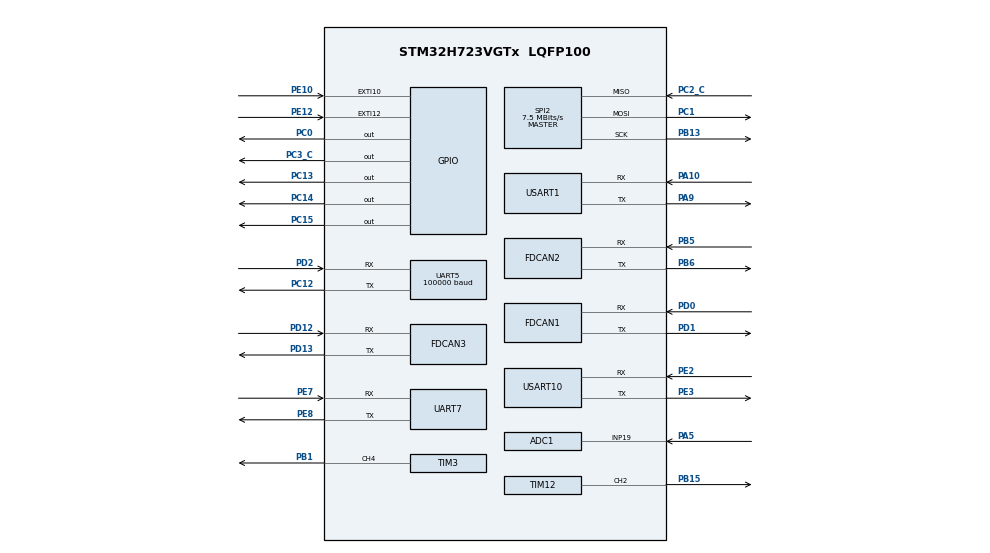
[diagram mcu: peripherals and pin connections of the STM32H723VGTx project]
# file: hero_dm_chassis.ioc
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ADC1.Channel-3\#ChannelRegularConversion=ADC_CHANNEL_19
ADC1.ClockPrescaler=ADC_CLOCK_ASYNC_DIV4
ADC1.ContinuousConvMode=ENABLE
ADC1.ConversionDataManagement=ADC_CONVERSIONDATA_DMA_CIRCULAR
ADC1.EnableInjectedConversion=DISABLE
ADC1.NbrOfConversionFlag=1
ADC1.OffsetNumber-3\#ChannelRegularConversion=ADC_OFFSET_NONE
ADC1.OffsetSignedSaturation-3\#ChannelRegularConversion=DISABLE
ADC1.Rank-3\#ChannelRegularConversion=1
ADC1.Ratio=1
ADC1.SamplingTime-3\#ChannelRegularConversion=ADC_SAMPLETIME_64CYCLES_5
ADC1.master=1
CORTEX_M7.default_mode_Activation=1
Dma.ADC1.5.Direction=DMA_PERIPH_TO_MEMORY
Dma.ADC1.5.EventEnable=DISABLE
Dma.ADC1.5.FIFOMode=DMA_FIFOMODE_DISABLE
Dma.ADC1.5.Instance=DMA1_Stream5
Dma.ADC1.5.MemDataAlignment=DMA_MDATAALIGN_HALFWORD
Dma.ADC1.5.MemInc=DMA_MINC_ENABLE
Dma.ADC1.5.Mode=DMA_CIRCULAR
Dma.ADC1.5.PeriphDataAlignment=DMA_PDATAALIGN_HALFWORD
Dma.ADC1.5.PeriphInc=DMA_PINC_DISABLE
Dma.ADC1.5.Polarity=HAL_DMAMUX_REQ_GEN_RISING
Dma.ADC1.5.Priority=DMA_PRIORITY_LOW
Dma.ADC1.5.RequestNumber=1
Dma.ADC1.5.SignalID=NONE
Dma.ADC1.5.SyncEnable=DISABLE
Dma.ADC1.5.SyncPolarity=HAL_DMAMUX_SYNC_NO_EVENT
Dma.ADC1.5.SyncRequestNumber=1
Dma.ADC1.5.SyncSignalID=NONE
Dma.Request0=UART7_RX
Dma.Request1=SPI2_RX
Dma.Request2=SPI2_TX
Dma.Request3=USART10_RX
Dma.Request4=UART5_RX
Dma.Request5=ADC1
Dma.Request6=USART10_TX
Dma.Request7=USART1_RX
Dma.SPI2_RX.1.Direction=DMA_PERIPH_TO_MEMORY
Dma.SPI2_RX.1.EventEnable=DISABLE
Dma.SPI2_RX.1.FIFOMode=DMA_FIFOMODE_DISABLE
Dma.SPI2_RX.1.Instance=DMA1_Stream0
Dma.SPI2_RX.1.MemDataAlignment=DMA_MDATAALIGN_BYTE
Dma.SPI2_RX.1.MemInc=DMA_MINC_ENABLE
Dma.SPI2_RX.1.Mode=DMA_NORMAL
Dma.SPI2_RX.1.PeriphDataAlignment=DMA_PDATAALIGN_BYTE
Dma.SPI2_RX.1.PeriphInc=DMA_PINC_DISABLE
Dma.SPI2_RX.1.Polarity=HAL_DMAMUX_REQ_GEN_RISING
Dma.SPI2_RX.1.Priority=DMA_PRIORITY_HIGH
Dma.SPI2_RX.1.RequestNumber=1
Dma.SPI2_RX.1.SignalID=NONE
Dma.SPI2_RX.1.SyncEnable=DISABLE
Dma.SPI2_RX.1.SyncPolarity=HAL_DMAMUX_SYNC_NO_EVENT
Dma.SPI2_RX.1.SyncRequestNumber=1
Dma.SPI2_RX.1.SyncSignalID=NONE
Dma.SPI2_TX.2.Direction=DMA_MEMORY_TO_PERIPH
Dma.SPI2_TX.2.EventEnable=DISABLE
Dma.SPI2_TX.2.FIFOMode=DMA_FIFOMODE_DISABLE
Dma.SPI2_TX.2.Instance=DMA1_Stream1
Dma.SPI2_TX.2.MemDataAlignment=DMA_MDATAALIGN_BYTE
Dma.SPI2_TX.2.MemInc=DMA_MINC_ENABLE
Dma.SPI2_TX.2.Mode=DMA_NORMAL
Dma.SPI2_TX.2.PeriphDataAlignment=DMA_PDATAALIGN_BYTE
Dma.SPI2_TX.2.PeriphInc=DMA_PINC_DISABLE
Dma.SPI2_TX.2.Polarity=HAL_DMAMUX_REQ_GEN_RISING
Dma.SPI2_TX.2.Priority=DMA_PRIORITY_HIGH
Dma.SPI2_TX.2.RequestNumber=1
Dma.SPI2_TX.2.SignalID=NONE
Dma.SPI2_TX.2.SyncEnable=DISABLE
Dma.SPI2_TX.2.SyncPolarity=HAL_DMAMUX_SYNC_NO_EVENT
Dma.SPI2_TX.2.SyncRequestNumber=1
Dma.SPI2_TX.2.SyncSignalID=NONE
Dma.UART5_RX.4.Direction=DMA_PERIPH_TO_MEMORY
Dma.UART5_RX.4.EventEnable=DISABLE
Dma.UART5_RX.4.FIFOMode=DMA_FIFOMODE_DISABLE
Dma.UART5_RX.4.Instance=DMA1_Stream4
Dma.UART5_RX.4.MemDataAlignment=DMA_MDATAALIGN_BYTE
Dma.UART5_RX.4.MemInc=DMA_MINC_ENABLE
Dma.UART5_RX.4.Mode=DMA_CIRCULAR
Dma.UART5_RX.4.PeriphDataAlignment=DMA_PDATAALIGN_BYTE
Dma.UART5_RX.4.PeriphInc=DMA_PINC_DISABLE
Dma.UART5_RX.4.Polarity=HAL_DMAMUX_REQ_GEN_RISING
Dma.UART5_RX.4.Priority=DMA_PRIORITY_LOW
Dma.UART5_RX.4.RequestNumber=1
Dma.UART5_RX.4.SignalID=NONE
Dma.UART5_RX.4.SyncEnable=DISABLE
Dma.UART5_RX.4.SyncPolarity=HAL_DMAMUX_SYNC_NO_EVENT
Dma.UART5_RX.4.SyncRequestNumber=1
Dma.UART5_RX.4.SyncSignalID=NONE
Dma.UART7_RX.0.Direction=DMA_PERIPH_TO_MEMORY
Dma.UART7_RX.0.EventEnable=DISABLE
Dma.UART7_RX.0.FIFOMode=DMA_FIFOMODE_DISABLE
Dma.UART7_RX.0.Instance=DMA1_Stream2
Dma.UART7_RX.0.MemDataAlignment=DMA_MDATAALIGN_BYTE
Dma.UART7_RX.0.MemInc=DMA_MINC_ENABLE
Dma.UART7_RX.0.Mode=DMA_NORMAL
Dma.UART7_RX.0.PeriphDataAlignment=DMA_PDATAALIGN_BYTE
Dma.UART7_RX.0.PeriphInc=DMA_PINC_DISABLE
Dma.UART7_RX.0.Polarity=HAL_DMAMUX_REQ_GEN_RISING
Dma.UART7_RX.0.Priority=DMA_PRIORITY_LOW
Dma.UART7_RX.0.RequestNumber=1
Dma.UART7_RX.0.SignalID=NONE
Dma.UART7_RX.0.SyncEnable=DISABLE
Dma.UART7_RX.0.SyncPolarity=HAL_DMAMUX_SYNC_NO_EVENT
Dma.UART7_RX.0.SyncRequestNumber=1
Dma.UART7_RX.0.SyncSignalID=NONE
Dma.USART10_RX.3.Direction=DMA_PERIPH_TO_MEMORY
Dma.USART10_RX.3.EventEnable=DISABLE
Dma.USART10_RX.3.FIFOMode=DMA_FIFOMODE_DISABLE
Dma.USART10_RX.3.Instance=DMA1_Stream3
Dma.USART10_RX.3.MemDataAlignment=DMA_MDATAALIGN_BYTE
Dma.USART10_RX.3.MemInc=DMA_MINC_ENABLE
Dma.USART10_RX.3.Mode=DMA_NORMAL
Dma.USART10_RX.3.PeriphDataAlignment=DMA_PDATAALIGN_BYTE
Dma.USART10_RX.3.PeriphInc=DMA_PINC_DISABLE
Dma.USART10_RX.3.Polarity=HAL_DMAMUX_REQ_GEN_RISING
Dma.USART10_RX.3.Priority=DMA_PRIORITY_LOW
Dma.USART10_RX.3.RequestNumber=1
Dma.USART10_RX.3.SignalID=NONE
Dma.USART10_RX.3.SyncEnable=DISABLE
Dma.USART10_RX.3.SyncPolarity=HAL_DMAMUX_SYNC_NO_EVENT
Dma.USART10_RX.3.SyncRequestNumber=1
Dma.USART10_RX.3.SyncSignalID=NONE
Dma.USART10_TX.6.Direction=DMA_MEMORY_TO_PERIPH
Dma.USART10_TX.6.EventEnable=DISABLE
Dma.USART10_TX.6.FIFOMode=DMA_FIFOMODE_DISABLE
Dma.USART10_TX.6.Instance=DMA1_Stream6
Dma.USART10_TX.6.MemDataAlignment=DMA_MDATAALIGN_BYTE
Dma.USART10_TX.6.MemInc=DMA_MINC_ENABLE
Dma.USART10_TX.6.Mode=DMA_NORMAL
Dma.USART10_TX.6.PeriphDataAlignment=DMA_PDATAALIGN_BYTE
Dma.USART10_TX.6.PeriphInc=DMA_PINC_DISABLE
Dma.USART10_TX.6.Polarity=HAL_DMAMUX_REQ_GEN_RISING
Dma.USART10_TX.6.Priority=DMA_PRIORITY_LOW
Dma.USART10_TX.6.RequestNumber=1
Dma.USART10_TX.6.SignalID=NONE
Dma.USART10_TX.6.SyncEnable=DISABLE
Dma.USART10_TX.6.SyncPolarity=HAL_DMAMUX_SYNC_NO_EVENT
Dma.USART10_TX.6.SyncRequestNumber=1
Dma.USART10_TX.6.SyncSignalID=NONE
Dma.USART1_RX.7.Direction=DMA_PERIPH_TO_MEMORY
Dma.USART1_RX.7.EventEnable=DISABLE
Dma.USART1_RX.7.FIFOMode=DMA_FIFOMODE_DISABLE
Dma.USART1_RX.7.Instance=DMA1_Stream7
Dma.USART1_RX.7.MemDataAlignment=DMA_MDATAALIGN_BYTE
Dma.USART1_RX.7.MemInc=DMA_MINC_ENABLE
Dma.USART1_RX.7.Mode=DMA_NORMAL
Dma.USART1_RX.7.PeriphDataAlignment=DMA_PDATAALIGN_BYTE
Dma.USART1_RX.7.PeriphInc=DMA_PINC_DISABLE
Dma.USART1_RX.7.Polarity=HAL_DMAMUX_REQ_GEN_RISING
Dma.USART1_RX.7.Priority=DMA_PRIORITY_LOW
Dma.USART1_RX.7.RequestNumber=1
Dma.USART1_RX.7.SignalID=NONE
Dma.USART1_RX.7.SyncEnable=DISABLE
Dma.USART1_RX.7.SyncPolarity=HAL_DMAMUX_SYNC_NO_EVENT
Dma.USART1_RX.7.SyncRequestNumber=1
Dma.USART1_RX.7.SyncSignalID=NONE
FDCAN1.CalculateBaudRateNominal=1000000
FDCAN1.CalculateTimeBitNominal=1000
FDCAN1.CalculateTimeQuantumNominal=41.666666666666664
FDCAN1.DataTimeSeg1=19
FDCAN1.DataTimeSeg2=4
FDCAN1.NominalPrescaler=4
FDCAN1.NominalSyncJumpWidth=4
FDCAN1.NominalTimeSeg1=19
FDCAN1.NominalTimeSeg2=4
FDCAN1.RxFifo0ElmtsNbr=16
FDCAN1.StdFiltersNbr=1
FDCAN1.TxFifoQueueElmtsNbr=8
FDCAN2.CalculateBaudRateNominal=1000000
FDCAN2.CalculateTimeBitNominal=1000
FDCAN2.CalculateTimeQuantumNominal=41.666666666666664
FDCAN2.DataSyncJumpWidth=5
FDCAN2.DataTimeSeg1=19
FDCAN2.DataTimeSeg2=4
FDCAN2.MessageRAMOffset=256
FDCAN2.NominalPrescaler=4
FDCAN2.NominalSyncJumpWidth=4
FDCAN2.NominalTimeSeg1=19
FDCAN2.NominalTimeSeg2=4
FDCAN2.RxFifo0ElmtsNbr=16
FDCAN2.StdFiltersNbr=1
FDCAN2.TxFifoQueueElmtsNbr=8
FDCAN3.CalculateBaudRateNominal=960000
FDCAN3.CalculateTimeBitNominal=1041
FDCAN3.CalculateTimeQuantumNominal=41.666666666666664
FDCAN3.DataPrescaler=4
FDCAN3.DataTimeSeg1=19
FDCAN3.DataTimeSeg2=5
FDCAN3.MessageRAMOffset=1708
FDCAN3.NominalPrescaler=4
FDCAN3.NominalTimeSeg1=19
FDCAN3.NominalTimeSeg2=5
FDCAN3.ProtocolException=ENABLE
FDCAN3.RxFifo0ElmtsNbr=16
FDCAN3.StdFiltersNbr=2
FDCAN3.TransmitPause=ENABLE
FDCAN3.TxFifoQueueElmtsNbr=8
FREERTOS.Tasks01=ui_task,16,512,StartDefaultTask,As weak,NULL,Dynamic,NULL,NULL;crg_test_task,8,512,Crg_test_Task,As weak,NULL,Dynamic,NULL,NULL;imu_task,41,1024,Imu_Task,As weak,NULL,Dynamic,NULL,NULL;referee_usart_t,24,128,Referee_Usart_Task,As weak,NULL,Dynamic,NULL,NULL;chassis_task,32,512,Chassis_Task,As weak,NULL,Dynamic,NULL,NULL
FREERTOS.configENABLE_FPU=1
FREERTOS.configTOTAL_HEAP_SIZE=24576
Mcu.Family=STM32H7
Mcu.Name=STM32H723VGTx
Mcu.Package=LQFP100
NVIC.DMA1_Stream0_IRQn=true\:5\:0\:false\:false\:true\:false\:false\:true\:true
NVIC.DMA1_Stream1_IRQn=true\:5\:0\:false\:false\:true\:false\:false\:true\:true
NVIC.DMA1_Stream2_IRQn=true\:5\:0\:true\:false\:true\:true\:false\:true\:true
NVIC.DMA1_Stream3_IRQn=true\:5\:0\:false\:false\:true\:true\:false\:true\:true
NVIC.DMA1_Stream4_IRQn=true\:5\:0\:false\:false\:true\:true\:false\:true\:true
NVIC.DMA1_Stream5_IRQn=true\:5\:0\:false\:false\:true\:true\:false\:true\:true
NVIC.DMA1_Stream6_IRQn=true\:5\:0\:false\:false\:true\:true\:false\:true\:true
NVIC.DMA1_Stream7_IRQn=true\:5\:0\:false\:false\:true\:true\:false\:true\:true
NVIC.EXTI15_10_IRQn=true\:5\:0\:false\:false\:true\:true\:true\:true\:true
NVIC.FDCAN1_IT0_IRQn=true\:5\:0\:false\:false\:true\:true\:true\:true\:true
NVIC.FDCAN2_IT0_IRQn=true\:5\:0\:false\:false\:true\:true\:true\:true\:true
NVIC.FDCAN3_IT0_IRQn=true\:6\:0\:true\:false\:true\:true\:true\:true\:true
NVIC.PriorityGroup=NVIC_PRIORITYGROUP_4
NVIC.SPI2_IRQn=true\:5\:0\:true\:false\:true\:true\:true\:true\:true
NVIC.TIM4_IRQn=true\:15\:0\:true\:false\:true\:false\:false\:true\:true
NVIC.TimeBase=TIM4_IRQn
NVIC.TimeBaseIP=TIM4
NVIC.UART5_IRQn=true\:5\:0\:false\:false\:true\:true\:true\:true\:true
NVIC.UART7_IRQn=true\:5\:0\:false\:false\:true\:true\:true\:true\:true
NVIC.USART10_IRQn=true\:5\:0\:false\:false\:true\:true\:true\:true\:true
PA10.Mode=Asynchronous
PA10.Signal=USART1_RX
PA5.Signal=ADCx_INP19
PA9.Mode=Asynchronous
PA9.Signal=USART1_TX
PB1.Signal=S_TIM3_CH4
PB13.Mode=Full_Duplex_Master
PB13.Signal=SPI2_SCK
PB15.Signal=S_TIM12_CH2
PB5.Mode=FDCAN_Activate
PB5.Signal=FDCAN2_RX
PB6.Mode=FDCAN_Activate
PB6.Signal=FDCAN2_TX
PC0.GPIO_PuPd=GPIO_PULLUP
PC0.PinState=GPIO_PIN_SET
PC0.Signal=GPIO_Output
PC1.Mode=Full_Duplex_Master
PC1.Signal=SPI2_MOSI
PC12.Mode=Asynchronous
PC12.Signal=UART5_TX
PC13.PinState=GPIO_PIN_SET
PC13.Signal=GPIO_Output
PC14-OSC32_IN.PinState=GPIO_PIN_SET
PC14-OSC32_IN.Signal=GPIO_Output
PC15-OSC32_OUT.PinState=GPIO_PIN_SET
PC15-OSC32_OUT.Signal=GPIO_Output
PC2_C.Mode=Full_Duplex_Master
PC2_C.Signal=SPI2_MISO
PC3_C.GPIO_PuPd=GPIO_PULLUP
PC3_C.PinState=GPIO_PIN_SET
PC3_C.Signal=GPIO_Output
PD0.Mode=FDCAN_Activate
PD0.Signal=FDCAN1_RX
PD1.Mode=FDCAN_Activate
PD1.Signal=FDCAN1_TX
PD12.Mode=FDCAN_Activate
PD12.Signal=FDCAN3_RX
PD13.Mode=FDCAN_Activate
PD13.Signal=FDCAN3_TX
PD2.Mode=Asynchronous
PD2.Signal=UART5_RX
PE10.GPIO_PuPd=GPIO_PULLUP
PE10.Signal=GPXTI10
PE12.GPIO_PuPd=GPIO_PULLUP
PE12.Signal=GPXTI12
PE2.Mode=Asynchronous
PE2.Signal=USART10_RX
PE3.Mode=Asynchronous
PE3.Signal=USART10_TX
PE7.Mode=Asynchronous
PE7.Signal=UART7_RX
PE8.Mode=Asynchronous
PE8.Signal=UART7_TX
PH0-OSC_IN.Mode=HSE-External-Oscillator
PH0-OSC_IN.Signal=RCC_OSC_IN
PH1-OSC_OUT.Mode=HSE-External-Oscillator
PH1-OSC_OUT.Signal=RCC_OSC_OUT
ProjectManager.HeapSize=0x200
ProjectManager.StackSize=0x400
ProjectManager.TargetToolchain=MDK-ARM V5.32
RCC.ADCFreq_Value=96000000
RCC.APB1Freq_Value=120000000
RCC.APB2Freq_Value=120000000
RCC.APB3Freq_Value=120000000
RCC.APB4Freq_Value=120000000
RCC.CortexFreq_Value=480000000
RCC.D1PPRE=RCC_APB3_DIV2
RCC.D2PPRE1=RCC_APB1_DIV2
RCC.D2PPRE2=RCC_APB2_DIV2
RCC.D3PPRE=RCC_APB4_DIV2
RCC.DIVM1=2
RCC.DIVM2=2
RCC.DIVN1=40
RCC.DIVN2=16
RCC.DIVP1=1
RCC.FDCANCLockSelection=RCC_FDCANCLKSOURCE_PLL2
RCC.HCLKFreq_Value=240000000
RCC.HPRE=RCC_HCLK_DIV2
RCC.HSE_VALUE=24000000
RCC.PLL2FRACN=0
RCC.PLL3FRACN=0
RCC.PLLFRACN=0
RCC.PLLSourceVirtual=RCC_PLLSOURCE_HSE
RCC.SYSCLKFreq_VALUE=480000000
RCC.SYSCLKSource=RCC_SYSCLKSOURCE_PLLCLK
RCC.USBFreq_Value=240000000
SH.ADCx_INP19.0=ADC1_INP19,IN19-Single-Ended
SH.S_TIM12_CH2.0=TIM12_CH2,PWM Generation2 CH2
SH.S_TIM3_CH4.0=TIM3_CH4,PWM Generation4 CH4
SPI2.BaudRatePrescaler=SPI_BAUDRATEPRESCALER_32
SPI2.CLKPhase=SPI_PHASE_2EDGE
SPI2.CLKPolarity=SPI_POLARITY_HIGH
SPI2.CalculateBaudRate=7.5 MBits/s
SPI2.DataSize=SPI_DATASIZE_8BIT
SPI2.Direction=SPI_DIRECTION_2LINES
SPI2.Mode=SPI_MODE_MASTER
SPI2.VirtualType=VM_MASTER
STMicroelectronics.X-CUBE-ALGOBUILD.1.5.0.LibraryCcDSPOoLibraryJjDSPOoLibrary=true
TIM12.Channel-PWM\ Generation2\ CH2=TIM_CHANNEL_2
TIM12.Period=999
TIM12.Prescaler=59
TIM3.Channel-PWM\ Generation4\ CH4=TIM_CHANNEL_4
TIM3.Period=4999
TIM6.Period=999
TIM6.Prescaler=239
UART5.BaudRate=100000
UART5.Parity=PARITY_EVEN
UART5.StopBits=UART_STOPBITS_2
UART5.WordLength=WORDLENGTH_9B
USART1.VirtualMode-Asynchronous=VM_ASYNC
USART10.VirtualMode=VM_ASYNC
VP_FREERTOS_VS_CMSIS_V2.Mode=CMSIS_V2
VP_MEMORYMAP_VS_MEMORYMAP.Mode=CurAppReg
VP_STMicroelectronics.X-CUBE-ALGOBUILD_VS_DSPOoLibraryJjLibrary_1.5.0_1.5.0.Mode=DSPOoLibraryJjLibrary
VP_SYS_VS_tim4.Mode=TIM4
VP_TIM6_VS_ClockSourceINT.Mode=Enable_Timer
board=custom

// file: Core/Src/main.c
/* USER CODE BEGIN Header */
/**
  ******************************************************************************
  * @file           : main.c
  * @brief          : Main program body
  ******************************************************************************
  * @attention
  *
  * Copyright (c) 2026 STMicroelectronics.
  * All rights reserved.
  *
  * This software is licensed under terms that can be found in the LICENSE file
  * in the root directory of this software component.
  * If no LICENSE file comes with this software, it is provided AS-IS.
  *
  ******************************************************************************
  */
/* USER CODE END Header */
#include "main.h"
#include "FreeRTOS.h"
#include "cmsis_os2.h"
#include "adc.h"
#include "dma.h"
#include "fdcan.h"
#include "spi.h"
#include "tim.h"
#include "usart.h"
#include "gpio.h"

void SystemClock_Config(void);
void PeriphCommonClock_Config(void);
static void MPU_Config(void);
void MX_FREERTOS_Init(void);

/**+
  * @brief  The application entry point.
  * @retval int
  */
int main(void)
{

  /* MPU Configuration--------------------------------------------------------*/
  MPU_Config();

  /* MCU Configuration--------------------------------------------------------*/

  /* Reset of all peripherals, Initializes the Flash interface and the Systick. */
  HAL_Init();

  /* Configure the system clock */
  SystemClock_Config();

  /* Configure the peripherals common clocks */
  PeriphCommonClock_Config();

  /* Initialize all configured peripherals */
  MX_GPIO_Init();
  MX_DMA_Init();
  MX_FDCAN1_Init();
  MX_FDCAN2_Init();
  MX_FDCAN3_Init();
  MX_SPI2_Init();
  MX_UART7_Init();
  MX_ADC1_Init();
  MX_TIM3_Init();
  MX_TIM6_Init();
  MX_TIM12_Init();
  MX_UART5_Init();
  MX_USART10_UART_Init();
  MX_USART1_UART_Init();
  /* USER CODE BEGIN 2 */
  /* Enable the DWT cycle counter: used by BMI088_delay_us().
     No debugger needed, TRCENA must be set once. */
  CoreDebug->DEMCR |= CoreDebug_DEMCR_TRCENA_Msk;
  DWT->CYCCNT = 0U;
  DWT->CTRL  |= DWT_CTRL_CYCCNTENA_Msk;

  /* USER CODE END 2 */

  /* Init scheduler */
  osKernelInitialize();  /* Call init function for freertos objects (in cmsis_os2.c) */
  MX_FREERTOS_Init();

  /* Start scheduler */
  osKernelStart();

  /* We should never get here as control is now taken by the scheduler */

  /* Infinite loop */
  while (1)
  {

  }
}

void SystemClock_Config(void)
{
  RCC_OscInitTypeDef RCC_OscInitStruct = {0};
  RCC_ClkInitTypeDef RCC_ClkInitStruct = {0};

  /** Supply configuration update enable
  */
  HAL_PWREx_ConfigSupply(PWR_LDO_SUPPLY);

  /** Configure the main internal regulator output voltage
  */
  __HAL_PWR_VOLTAGESCALING_CONFIG(PWR_REGULATOR_VOLTAGE_SCALE0);

  while(!__HAL_PWR_GET_FLAG(PWR_FLAG_VOSRDY)) {}

  /** Initializes the RCC Oscillators according to the specified parameters
  * in the RCC_OscInitTypeDef structure.
  */
  RCC_OscInitStruct.OscillatorType = RCC_OSCILLATORTYPE_HSE;
  RCC_OscInitStruct.HSEState = RCC_HSE_ON;
  RCC_OscInitStruct.PLL.PLLState = RCC_PLL_ON;
  RCC_OscInitStruct.PLL.PLLSource = RCC_PLLSOURCE_HSE;
  RCC_OscInitStruct.PLL.PLLM = 2;
  RCC_OscInitStruct.PLL.PLLN = 40;
  RCC_OscInitStruct.PLL.PLLP = 1;
  RCC_OscInitStruct.PLL.PLLQ = 2;
  RCC_OscInitStruct.PLL.PLLR = 2;
  RCC_OscInitStruct.PLL.PLLRGE = RCC_PLL1VCIRANGE_3;
  RCC_OscInitStruct.PLL.PLLVCOSEL = RCC_PLL1VCOWIDE;
  RCC_OscInitStruct.PLL.PLLFRACN = 0;
  if (HAL_RCC_OscConfig(&RCC_OscInitStruct) != HAL_OK)
  {
    Error_Handler();
  }

  /** Initializes the CPU, AHB and APB buses clocks
  */
  RCC_ClkInitStruct.ClockType = RCC_CLOCKTYPE_HCLK|RCC_CLOCKTYPE_SYSCLK
                              |RCC_CLOCKTYPE_PCLK1|RCC_CLOCKTYPE_PCLK2
                              |RCC_CLOCKTYPE_D3PCLK1|RCC_CLOCKTYPE_D1PCLK1;
  RCC_ClkInitStruct.SYSCLKSource = RCC_SYSCLKSOURCE_PLLCLK;
  RCC_ClkInitStruct.SYSCLKDivider = RCC_SYSCLK_DIV1;
  RCC_ClkInitStruct.AHBCLKDivider = RCC_HCLK_DIV2;
  RCC_ClkInitStruct.APB3CLKDivider = RCC_APB3_DIV2;
  RCC_ClkInitStruct.APB1CLKDivider = RCC_APB1_DIV2;
  RCC_ClkInitStruct.APB2CLKDivider = RCC_APB2_DIV2;
  RCC_ClkInitStruct.APB4CLKDivider = RCC_APB4_DIV2;

  if (HAL_RCC_ClockConfig(&RCC_ClkInitStruct, FLASH_LATENCY_3) != HAL_OK)
  {
    Error_Handler();
  }
}

void PeriphCommonClock_Config(void)
{
  RCC_PeriphCLKInitTypeDef PeriphClkInitStruct = {0};

  /** Initializes the peripherals clock
  */
  PeriphClkInitStruct.PeriphClockSelection = RCC_PERIPHCLK_ADC|RCC_PERIPHCLK_FDCAN;
  PeriphClkInitStruct.PLL2.PLL2M = 2;
  PeriphClkInitStruct.PLL2.PLL2N = 16;
  PeriphClkInitStruct.PLL2.PLL2P = 2;
  PeriphClkInitStruct.PLL2.PLL2Q = 2;
  PeriphClkInitStruct.PLL2.PLL2R = 2;
  PeriphClkInitStruct.PLL2.PLL2RGE = RCC_PLL2VCIRANGE_3;
  PeriphClkInitStruct.PLL2.PLL2VCOSEL = RCC_PLL2VCOWIDE;
  PeriphClkInitStruct.PLL2.PLL2FRACN = 0;
  PeriphClkInitStruct.FdcanClockSelection = RCC_FDCANCLKSOURCE_PLL2;
  PeriphClkInitStruct.AdcClockSelection = RCC_ADCCLKSOURCE_PLL2;
  if (HAL_RCCEx_PeriphCLKConfig(&PeriphClkInitStruct) != HAL_OK)
  {
    Error_Handler();
  }
}

 /* MPU Configuration */

void MPU_Config(void)
{
  MPU_Region_InitTypeDef MPU_InitStruct = {0};

  /* Disables the MPU */
  HAL_MPU_Disable();

  /** Initializes and configures the Region and the memory to be protected
  */
  MPU_InitStruct.Enable = MPU_REGION_ENABLE;
  MPU_InitStruct.Number = MPU_REGION_NUMBER0;
  MPU_InitStruct.BaseAddress = 0x0;
  MPU_InitStruct.Size = MPU_REGION_SIZE_4GB;
  MPU_InitStruct.SubRegionDisable = 0x87;
  MPU_InitStruct.TypeExtField = MPU_TEX_LEVEL0;
  MPU_InitStruct.AccessPermission = MPU_REGION_NO_ACCESS;
  MPU_InitStruct.DisableExec = MPU_INSTRUCTION_ACCESS_DISABLE;
  MPU_InitStruct.IsShareable = MPU_ACCESS_SHAREABLE;
  MPU_InitStruct.IsCacheable = MPU_ACCESS_NOT_CACHEABLE;
  MPU_InitStruct.IsBufferable = MPU_ACCESS_NOT_BUFFERABLE;

  HAL_MPU_ConfigRegion(&MPU_InitStruct);
  /* Enables the MPU */
  HAL_MPU_Enable(MPU_PRIVILEGED_DEFAULT);

}

void HAL_TIM_PeriodElapsedCallback(TIM_HandleTypeDef *htim)
{
  if (htim->Instance == TIM4)
  {
    HAL_IncTick();
  }
}

void Error_Handler(void)
{
  __disable_irq();
  while (1)
  {
  }
}

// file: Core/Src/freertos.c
/* USER CODE BEGIN Header */
/**
  ******************************************************************************
  * File Name          : freertos.c
  * Description        : Code for freertos applications
  ******************************************************************************
  * @attention
  *
  * Copyright (c) 2026 STMicroelectronics.
  * All rights reserved.
  *
  * This software is licensed under terms that can be found in the LICENSE file
  * in the root directory of this software component.
  * If no LICENSE file comes with this software, it is provided AS-IS.
  *
  ******************************************************************************
  */
/* USER CODE END Header */

#include "FreeRTOS.h"
#include "task.h"
#include "main.h"
#include "FreeRTOS.h"
#include "cmsis_os2.h"

/* Definitions for ui_task */
osThreadId_t ui_taskHandle;
const osThreadAttr_t ui_task_attributes = {
  .name = "ui_task",
  .stack_size = 512 * 4,
  .priority = (osPriority_t) osPriorityBelowNormal,
};
/* Definitions for crg_test_task */
osThreadId_t crg_test_taskHandle;
const osThreadAttr_t crg_test_task_attributes = {
  .name = "crg_test_task",
  .stack_size = 512 * 4,
  .priority = (osPriority_t) osPriorityLow,
};
/* Definitions for imu_task */
osThreadId_t imu_taskHandle;
const osThreadAttr_t imu_task_attributes = {
  .name = "imu_task",
  .stack_size = 1024 * 4,
  .priority = (osPriority_t) osPriorityHigh1,
};
/* Definitions for referee_usart_t */
osThreadId_t referee_usart_tHandle;
const osThreadAttr_t referee_usart_t_attributes = {
  .name = "referee_usart_t",
  .stack_size = 128 * 4,
  .priority = (osPriority_t) osPriorityNormal,
};
/* Definitions for chassis_task */
osThreadId_t chassis_taskHandle;
const osThreadAttr_t chassis_task_attributes = {
  .name = "chassis_task",
  .stack_size = 512 * 4,
  .priority = (osPriority_t) osPriorityAboveNormal,
};

void StartDefaultTask(void *argument);
void Crg_test_Task(void *argument);
void Imu_Task(void *argument);
void Referee_Usart_Task(void *argument);
void Chassis_Task(void *argument);

void MX_FREERTOS_Init(void); /* (MISRA C 2004 rule 8.1) */

void MX_FREERTOS_Init(void) {

  /* Create the thread(s) */
  /* creation of ui_task */
  //ui_taskHandle = osThreadNew(StartDefaultTask, NULL, &ui_task_attributes);

  /* creation of crg_test_task */
  //crg_test_taskHandle = osThreadNew(Crg_test_Task, NULL, &crg_test_task_attributes);

  /* creation of imu_task */
  imu_taskHandle = osThreadNew(Imu_Task, NULL, &imu_task_attributes);

  /* creation of referee_usart_t */
  //referee_usart_tHandle = osThreadNew(Referee_Usart_Task, NULL, &referee_usart_t_attributes);

  /* creation of chassis_task */
  chassis_taskHandle = osThreadNew(Chassis_Task, NULL, &chassis_task_attributes);

}

__weak void StartDefaultTask(void *argument)
{
  for(;;)
  {
    osDelay(1);
  }
}

__weak void Crg_test_Task(void *argument)
{
  /* USER CODE BEGIN Crg_test_Task */
  /* 测试任务已停用：CAN 逻辑已迁移到 chassis_task / can_user.c。 */
  for(;;)
  {
    osDelay(1);
  }
  /* USER CODE END Crg_test_Task */
}

__weak void Imu_Task(void *argument)
{
  for(;;)
  {
    osDelay(1);
  }
}

__weak void Referee_Usart_Task(void *argument)
{
  for(;;)
  {
    osDelay(1);
  }
}

__weak void Chassis_Task(void *argument)
{
  for(;;)
  {
    osDelay(1);
  }
}
